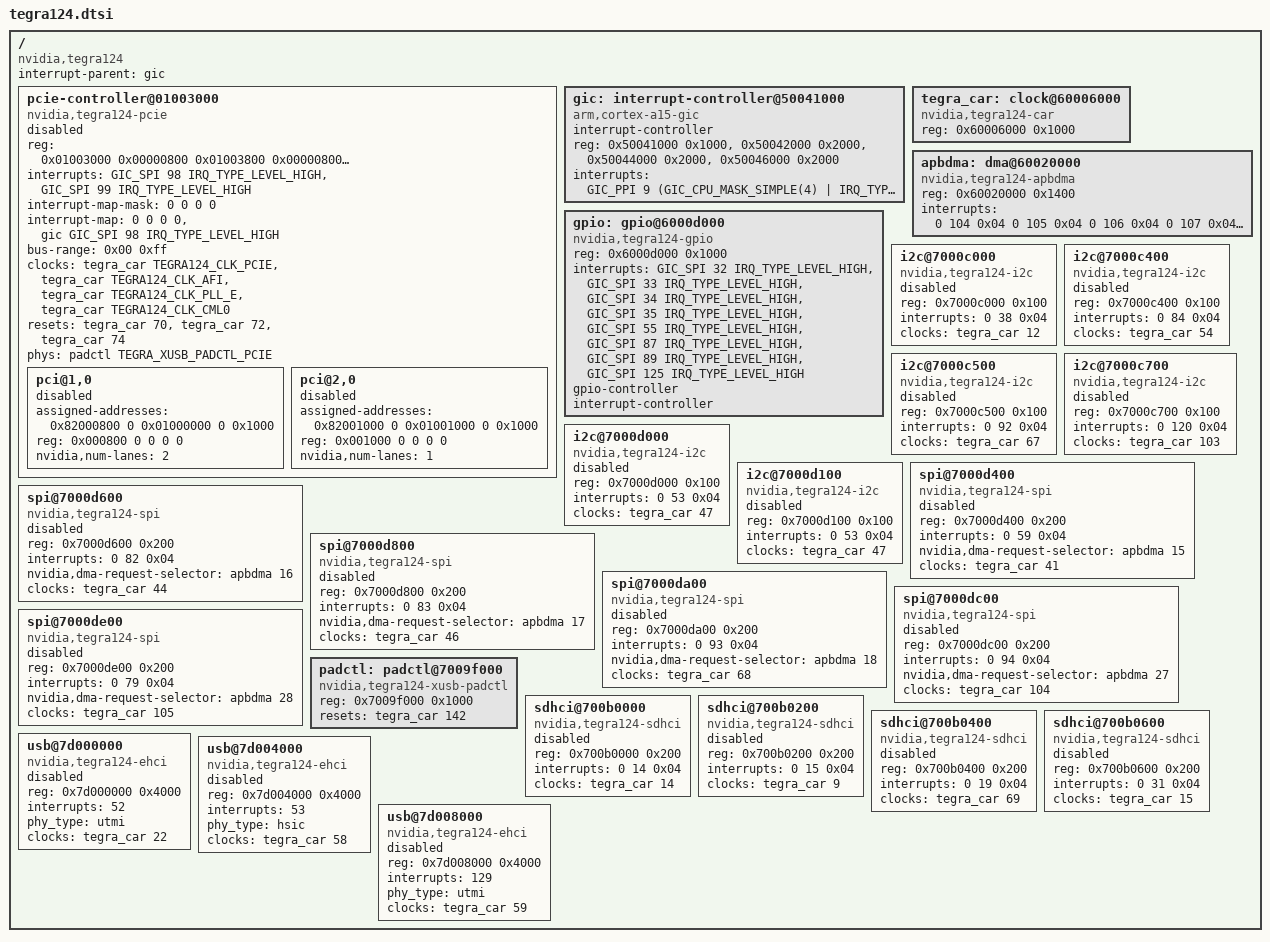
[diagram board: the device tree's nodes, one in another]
#include <dt-bindings/clock/tegra124-car.h>
#include <dt-bindings/gpio/tegra-gpio.h>
#include <dt-bindings/interrupt-controller/arm-gic.h>
#include <dt-bindings/pinctrl/pinctrl-tegra-xusb.h>

#include "skeleton.dtsi"

/ {
	compatible = "nvidia,tegra124";
	interrupt-parent = <&gic>;

	pcie-controller@01003000 {
		compatible = "nvidia,tegra124-pcie";
		device_type = "pci";
		reg = <0x01003000 0x00000800   /* PADS registers */
		       0x01003800 0x00000800   /* AFI registers */
		       0x02000000 0x10000000>; /* configuration space */
		reg-names = "pads", "afi", "cs";
		interrupts = <GIC_SPI 98 IRQ_TYPE_LEVEL_HIGH>, /* controller interrupt */
			     <GIC_SPI 99 IRQ_TYPE_LEVEL_HIGH>; /* MSI interrupt */
		interrupt-names = "intr", "msi";

		#interrupt-cells = <1>;
		interrupt-map-mask = <0 0 0 0>;
		interrupt-map = <0 0 0 0 &gic GIC_SPI 98 IRQ_TYPE_LEVEL_HIGH>;

		bus-range = <0x00 0xff>;
		#address-cells = <3>;
		#size-cells = <2>;

		ranges = <0x82000000 0 0x01000000 0x01000000 0 0x00001000   /* port 0 configuration space */
			  0x82000000 0 0x01001000 0x01001000 0 0x00001000   /* port 1 configuration space */
			  0x81000000 0 0x0        0x12000000 0 0x00010000   /* downstream I/O (64 KiB) */
			  0x82000000 0 0x13000000 0x13000000 0 0x0d000000   /* non-prefetchable memory (208 MiB) */
			  0xc2000000 0 0x20000000 0x20000000 0 0x20000000>; /* prefetchable memory (512 MiB) */

		clocks = <&tegra_car TEGRA124_CLK_PCIE>,
			 <&tegra_car TEGRA124_CLK_AFI>,
			 <&tegra_car TEGRA124_CLK_PLL_E>,
			 <&tegra_car TEGRA124_CLK_CML0>;
		clock-names = "pex", "afi", "pll_e", "cml";
		resets = <&tegra_car 70>,
			 <&tegra_car 72>,
			 <&tegra_car 74>;
		reset-names = "pex", "afi", "pcie_x";
		status = "disabled";

		phys = <&padctl TEGRA_XUSB_PADCTL_PCIE>;
		phy-names = "pcie";

		pci@1,0 {
			device_type = "pci";
			assigned-addresses = <0x82000800 0 0x01000000 0 0x1000>;
			reg = <0x000800 0 0 0 0>;
			status = "disabled";

			#address-cells = <3>;
			#size-cells = <2>;
			ranges;

			nvidia,num-lanes = <2>;
		};

		pci@2,0 {
			device_type = "pci";
			assigned-addresses = <0x82001000 0 0x01001000 0 0x1000>;
			reg = <0x001000 0 0 0 0>;
			status = "disabled";

			#address-cells = <3>;
			#size-cells = <2>;
			ranges;

			nvidia,num-lanes = <1>;
		};
	};

	gic: interrupt-controller@50041000 {
		compatible = "arm,cortex-a15-gic";
		#interrupt-cells = <3>;
		interrupt-controller;
		reg = <0x50041000 0x1000>,
		      <0x50042000 0x2000>,
		      <0x50044000 0x2000>,
		      <0x50046000 0x2000>;
		interrupts = <GIC_PPI 9
			(GIC_CPU_MASK_SIMPLE(4) | IRQ_TYPE_LEVEL_HIGH)>;
	};

	tegra_car: clock@60006000 {
		compatible = "nvidia,tegra124-car";
		reg = <0x60006000 0x1000>;
		#clock-cells = <1>;
	};

	apbdma: dma@60020000 {
		compatible = "nvidia,tegra124-apbdma", "nvidia,tegra148-apbdma";
		reg = <0x60020000 0x1400>;
		interrupts = <0 104 0x04
			      0 105 0x04
			      0 106 0x04
			      0 107 0x04
			      0 108 0x04
			      0 109 0x04
			      0 110 0x04
			      0 111 0x04
			      0 112 0x04
			      0 113 0x04
			      0 114 0x04
			      0 115 0x04
			      0 116 0x04
			      0 117 0x04
			      0 118 0x04
			      0 119 0x04
			      0 128 0x04
			      0 129 0x04
			      0 130 0x04
			      0 131 0x04
			      0 132 0x04
			      0 133 0x04
			      0 134 0x04
			      0 135 0x04
			      0 136 0x04
			      0 137 0x04
			      0 138 0x04
			      0 139 0x04
			      0 140 0x04
			      0 141 0x04
			      0 142 0x04
			      0 143 0x04>;
	};

	gpio: gpio@6000d000 {
		compatible = "nvidia,tegra124-gpio", "nvidia,tegra30-gpio";
		reg = <0x6000d000 0x1000>;
		interrupts = <GIC_SPI 32 IRQ_TYPE_LEVEL_HIGH>,
			     <GIC_SPI 33 IRQ_TYPE_LEVEL_HIGH>,
			     <GIC_SPI 34 IRQ_TYPE_LEVEL_HIGH>,
			     <GIC_SPI 35 IRQ_TYPE_LEVEL_HIGH>,
			     <GIC_SPI 55 IRQ_TYPE_LEVEL_HIGH>,
			     <GIC_SPI 87 IRQ_TYPE_LEVEL_HIGH>,
			     <GIC_SPI 89 IRQ_TYPE_LEVEL_HIGH>,
			     <GIC_SPI 125 IRQ_TYPE_LEVEL_HIGH>;
		#gpio-cells = <2>;
		gpio-controller;
		#interrupt-cells = <2>;
		interrupt-controller;
	};

	i2c@7000c000 {
		compatible = "nvidia,tegra124-i2c", "nvidia,tegra114-i2c";
		reg = <0x7000c000 0x100>;
		interrupts = <0 38 0x04>;
		#address-cells = <1>;
		#size-cells = <0>;
		clocks = <&tegra_car 12>;
		status = "disabled";
	};

	i2c@7000c400 {
		compatible = "nvidia,tegra124-i2c", "nvidia,tegra114-i2c";
		reg = <0x7000c400 0x100>;
		interrupts = <0 84 0x04>;
		#address-cells = <1>;
		#size-cells = <0>;
		clocks = <&tegra_car 54>;
		status = "disabled";
	};

	i2c@7000c500 {
		compatible = "nvidia,tegra124-i2c", "nvidia,tegra114-i2c";
		reg = <0x7000c500 0x100>;
		interrupts = <0 92 0x04>;
		#address-cells = <1>;
		#size-cells = <0>;
		clocks = <&tegra_car 67>;
		status = "disabled";
	};

	i2c@7000c700 {
		compatible = "nvidia,tegra124-i2c", "nvidia,tegra114-i2c";
		reg = <0x7000c700 0x100>;
		interrupts = <0 120 0x04>;
		#address-cells = <1>;
		#size-cells = <0>;
		clocks = <&tegra_car 103>;
		status = "disabled";
	};

	i2c@7000d000 {
		compatible = "nvidia,tegra124-i2c", "nvidia,tegra114-i2c";
		reg = <0x7000d000 0x100>;
		interrupts = <0 53 0x04>;
		#address-cells = <1>;
		#size-cells = <0>;
		clocks = <&tegra_car 47>;
		status = "disabled";
	};

	i2c@7000d100 {
		compatible = "nvidia,tegra124-i2c", "nvidia,tegra114-i2c";
		reg = <0x7000d100 0x100>;
		interrupts = <0 53 0x04>;
		#address-cells = <1>;
		#size-cells = <0>;
		clocks = <&tegra_car 47>;
		status = "disabled";
	};

	spi@7000d400 {
		compatible = "nvidia,tegra124-spi", "nvidia,tegra114-spi";
		reg = <0x7000d400 0x200>;
		interrupts = <0 59 0x04>;
		nvidia,dma-request-selector = <&apbdma 15>;
		#address-cells = <1>;
		#size-cells = <0>;
		status = "disabled";
		clocks = <&tegra_car 41>;
	};

	spi@7000d600 {
		compatible = "nvidia,tegra124-spi", "nvidia,tegra114-spi";
		reg = <0x7000d600 0x200>;
		interrupts = <0 82 0x04>;
		nvidia,dma-request-selector = <&apbdma 16>;
		#address-cells = <1>;
		#size-cells = <0>;
		status = "disabled";
		clocks = <&tegra_car 44>;
	};

	spi@7000d800 {
		compatible = "nvidia,tegra124-spi", "nvidia,tegra114-spi";
		reg = <0x7000d800 0x200>;
		interrupts = <0 83 0x04>;
		nvidia,dma-request-selector = <&apbdma 17>;
		#address-cells = <1>;
		#size-cells = <0>;
		status = "disabled";
		clocks = <&tegra_car 46>;
	};

	spi@7000da00 {
		compatible = "nvidia,tegra124-spi", "nvidia,tegra114-spi";
		reg = <0x7000da00 0x200>;
		interrupts = <0 93 0x04>;
		nvidia,dma-request-selector = <&apbdma 18>;
		#address-cells = <1>;
		#size-cells = <0>;
		status = "disabled";
		clocks = <&tegra_car 68>;
	};

	spi@7000dc00 {
		compatible = "nvidia,tegra124-spi", "nvidia,tegra114-spi";
		reg = <0x7000dc00 0x200>;
		interrupts = <0 94 0x04>;
		nvidia,dma-request-selector = <&apbdma 27>;
		#address-cells = <1>;
		#size-cells = <0>;
		status = "disabled";
		clocks = <&tegra_car 104>;
	};

	spi@7000de00 {
		compatible = "nvidia,tegra124-spi", "nvidia,tegra114-spi";
		reg = <0x7000de00 0x200>;
		interrupts = <0 79 0x04>;
		nvidia,dma-request-selector = <&apbdma 28>;
		#address-cells = <1>;
		#size-cells = <0>;
		status = "disabled";
		clocks = <&tegra_car 105>;
	};

	padctl: padctl@7009f000 {
		compatible = "nvidia,tegra124-xusb-padctl";
		reg = <0x7009f000 0x1000>;
		resets = <&tegra_car 142>;
		reset-names = "padctl";

		#phy-cells = <1>;
	};

	sdhci@700b0000 {
		compatible = "nvidia,tegra124-sdhci";
		reg = <0x700b0000 0x200>;
		interrupts = <0 14 0x04>;
		clocks = <&tegra_car 14>;
		status = "disabled";
	};

	sdhci@700b0200 {
		compatible = "nvidia,tegra124-sdhci";
		reg = <0x700b0200 0x200>;
		interrupts = <0 15 0x04>;
		clocks = <&tegra_car 9>;
		status = "disabled";
	};

	sdhci@700b0400 {
		compatible = "nvidia,tegra124-sdhci";
		reg = <0x700b0400 0x200>;
		interrupts = <0 19 0x04>;
		clocks = <&tegra_car 69>;
		status = "disabled";
	};

	sdhci@700b0600 {
		compatible = "nvidia,tegra124-sdhci";
		reg = <0x700b0600 0x200>;
		interrupts = <0 31 0x04>;
		clocks = <&tegra_car 15>;
		status = "disabled";
	};

	usb@7d000000 {
		compatible = "nvidia,tegra124-ehci", "nvidia,tegra30-ehci";
		reg = <0x7d000000 0x4000>;
		interrupts = < 52 >;
		phy_type = "utmi";
		clocks = <&tegra_car 22>;	/* PERIPH_ID_USBD */
		status = "disabled";
	};

	usb@7d004000 {
		compatible = "nvidia,tegra124-ehci", "nvidia,tegra30-ehci";
		reg = <0x7d004000 0x4000>;
		interrupts = < 53 >;
		phy_type = "hsic";
		clocks = <&tegra_car 58>;	/* PERIPH_ID_USB2 */
		status = "disabled";
	};

	usb@7d008000 {
		compatible = "nvidia,tegra124-ehci", "nvidia,tegra30-ehci";
		reg = <0x7d008000 0x4000>;
		interrupts = < 129 >;
		phy_type = "utmi";
		clocks = <&tegra_car 59>;	/* PERIPH_ID_USB3 */
		status = "disabled";
	};
};
